# S32K312_M7 register map
Vendor: NXP Semiconductors; File version: 1.3
CPU: CM7 r0p1, little endian, MPU, FPU, VTOR, 4 interrupt priority bits
Registers are 32-bit, read-write, reset 0x0 unless marked. A register's access mark holds for its fields unless they carry their own. Offsets are from the block's base; [hi:lo] are bit positions; {n}, {i} and the like mark numbered series; 'fields as' and 'values as' point back to an identical list.

## PMC
Base 0x402E8000
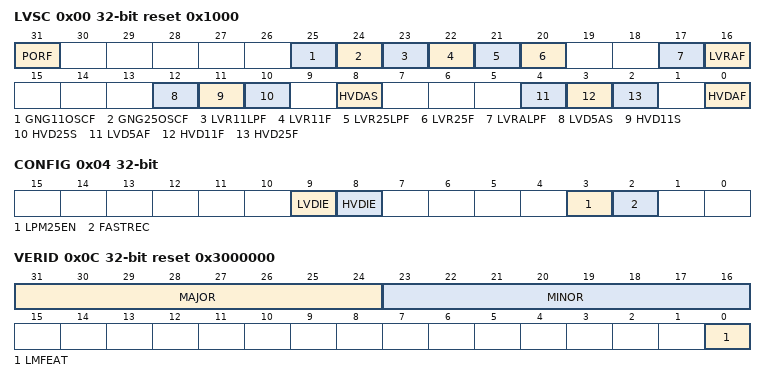
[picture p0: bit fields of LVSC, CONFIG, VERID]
0x00 LVSC reset 0x1000 (reset mask 0x7C0CFFFF) — Low Voltage Status And Control
  [31] PORF write-1-clears — POR Flag
    on read: 0=EVENT_NO (Event did not occur); 1=EVENT_YES (Event occurred)
  [25] GNG11OSCF write-1-clears — Go/No Go Detect Flag On OSC Part Of V11 Power Domain
    values as PORF
  [24] GNG25OSCF write-1-clears — Go/No Go Detect Flag On OSC Part of V25 Power Domain
    values as PORF
  [23] LVR11LPF write-1-clears — LVR11LP Flag On V11 Power Domain
    values as PORF
  [22] LVR11F write-1-clears — LVR11 Flag On V11 Power Domain In FPM
    values as PORF
  [21] LVR25LPF write-1-clears — LVR25LP Flag On V25 Power Domain
    values as PORF
  [20] LVR25F write-1-clears — LVR25 Flag On V25 Power Domain In FPM
    values as PORF
  [17] LVRALPF write-1-clears — LVRALP Flag On VDD_HV_A Power Domain
    values as PORF
  [16] LVRAF write-1-clears — LVRA Flag On VDD_HV_A Power Domain In FPM
    values as PORF
  [12] LVD5AS ro — LVD5A Status On VDD_HV_A Power Domain In FPM
    0=VOLTAGE_HIGH_TYP5 (Above); 1=VOLTAGE_LOW_TYP33 (Below)
  [11] HVD11S ro — HVD11 Status On V11 Power Domain In FPM
    0=VOLTAGE_GOOD (Voltage is below threshold or chip is in LPM); 1=VOLTAGE_TOO_HIGH (Voltage is above threshold and chip is in FPM)
  [10] HVD25S ro — HVD25 Status On V25 Power Domain In FPM
    values as HVD11S
  [8] HVDAS ro — HVDA Status On VDD_HV_A Power Domain In FPM
    values as HVD11S
  [4] LVD5AF write-1-clears — LVD5A Flag On VDD_HV_A Power Domain In FPM
    on read: 0=CHANGE_NO (Did not change); 1=CHANGE_YES (Changed)
  [3] HVD11F write-1-clears — HVD11 Flag On V11 Power Domain In FPM
    values as LVD5AF
  [2] HVD25F write-1-clears — HVD25 Flag On V25 Power Domain In FPM
    values as LVD5AF
  [0] HVDAF write-1-clears — HVDA Flag On VDD_HV_A Power Domain In FPM
    values as LVD5AF
0x04 CONFIG — PMC Configuration
  [9] LVDIE — Low Voltage Detect Interrupt Enable
    0=DISABLE (LVD hardware interrupt is disabled (use polling)); 1=ENABLE (Request an LVD hardware interrupt when LVDA5F = 1)
  [8] HVDIE — High Voltage Detect Interrupt Enable
    0=DISABLE (HVD hardware interrupt is disabled (use polling)); 1=ENABLE (Request an HVD hardware interrupt when HVDAF=1, HVDBF=1, HVD25F=1, or HVD11F=1)
  [3] LPM25EN — V25 Power Domain Enable During LPM
    0=DISABLE (Disabled); 1=ENABLE (Enabled)
  [2] FASTREC — Fast Recovery From LPM Enable
    0=DISABLE (Normal); 1=ENABLE (Fast)
0x0C VERID ro reset 0x3000000 — Version ID
  [31:24] MAJOR — Major Version Number
  [23:16] MINOR — Minor Version Number
  [0] LMFEAT — Last-Mile Regulator Feature
    0=DISABLE (Not available); 1=ENABLE (Available)

## TEMPSENSE
Base 0x4037C000
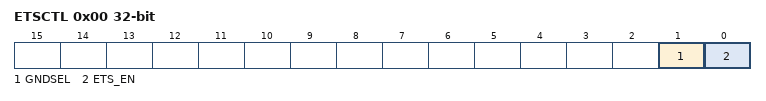
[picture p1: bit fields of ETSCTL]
0x00 ETSCTL — ETS Control
  [1] GNDSEL — Ground selection
    0=No exposure of the ground; 1=Expose ground on the ADC output if ETS_EN=1
  [0] ETS_EN — Temperature Sensor enable
    0=Power down; 1=Functional mode
{0x8+4i} TCA{i} ro reset not defined (i=0..2) — Temperature Coefficient
  [15:0] TCA{i} — Temperature coefficient A{i}

## CRC
Base 0x40380000
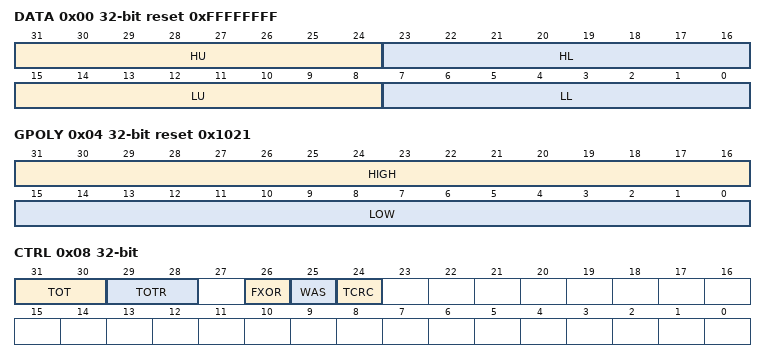
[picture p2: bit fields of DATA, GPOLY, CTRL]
0x00 DATA reset 0xFFFFFFFF — CRC DATA register
  [31:24] HU — CRC High Upper Byte
  [23:16] HL — CRC High Lower Byte
  [15:8] LU — CRC Low Upper Byte
  [7:0] LL — CRC Low Lower Byte
0x04 GPOLY reset 0x1021 — CRC Polynomial register
  [31:16] HIGH — High Polynominal Half-word
  [15:0] LOW — Low Polynominal Half-word
0x08 CTRL — CRC Control register
  [31:30] TOT — Type Of Transpose For Writes
    0=No transposition; 1=Bits in bytes are transposed; bytes are not transposed; 2=Both bits in bytes and bytes are transposed; 3=Only bytes are transposed; no bits in a byte are transposed
  [29:28] TOTR — Type Of Transpose For Read
    values as TOT
  [26] FXOR — Complement Read Of CRC DATA register
    0=No XOR on reading; 1=Invert or complement the read value of the CRC DATA register
  [25] WAS — Write CRC DATA register As Seed
    0=Writes to the CRC DATA register are data values; 1=Writes to the CRC DATA register are seed values
  [24] TCRC
    0=16-bit CRC protocol; 1=32-bit CRC protocol
